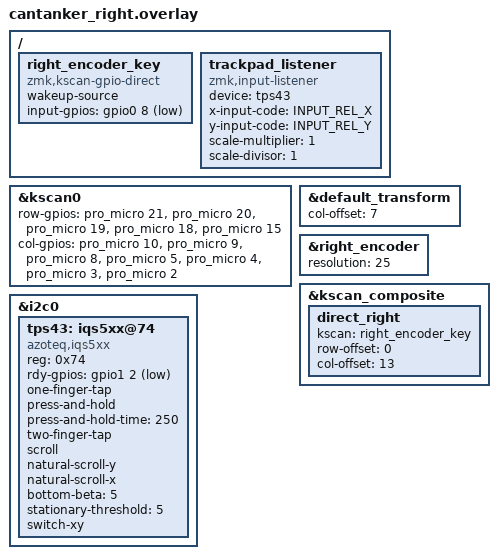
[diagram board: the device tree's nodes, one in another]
#include "cantanker.dtsi"
#include <dt-bindings/input/input-event-codes.h>

&kscan0 {
    row-gpios
        = <&pro_micro 21 (GPIO_ACTIVE_HIGH | GPIO_PULL_DOWN)>
        , <&pro_micro 20 (GPIO_ACTIVE_HIGH | GPIO_PULL_DOWN)>
        , <&pro_micro 19 (GPIO_ACTIVE_HIGH | GPIO_PULL_DOWN)>
        , <&pro_micro 18 (GPIO_ACTIVE_HIGH | GPIO_PULL_DOWN)>
        , <&pro_micro 15 (GPIO_ACTIVE_HIGH | GPIO_PULL_DOWN)>
        ;

    col-gpios
        = <&pro_micro 10 GPIO_ACTIVE_HIGH>
        , <&pro_micro 9  GPIO_ACTIVE_HIGH>
        , <&pro_micro 8  GPIO_ACTIVE_HIGH>
        , <&pro_micro 5  GPIO_ACTIVE_HIGH>
        , <&pro_micro 4  GPIO_ACTIVE_HIGH>
        , <&pro_micro 3  GPIO_ACTIVE_HIGH>
        , <&pro_micro 2  GPIO_ACTIVE_HIGH>
        ;
};

&default_transform {
    col-offset = <7>;
};

&right_encoder {
    status = "okay";
    resolution = <25>;
};

/ {
    right_encoder_key: right_encoder_key {
        compatible = "zmk,kscan-gpio-direct";
        wakeup-source;
        input-gpios = <&gpio0 8 (GPIO_ACTIVE_LOW | GPIO_PULL_UP)>;
    };
};

&kscan_composite {
    direct_right {
        kscan = <&right_encoder_key>;
        row-offset = <0>;
        col-offset = <13>;
    };
};

&i2c0 {
    status = "okay";
    
    tps43: iqs5xx@74 {
        status = "okay";
        compatible = "azoteq,iqs5xx";
        reg = <0x74>;

        rdy-gpios = <&gpio1 2 (GPIO_ACTIVE_LOW | GPIO_PULL_UP)>;

        /*
         * Potentially non-exhaustive list of configuration options.
         * See: dts/bindings/input/azoteq,iqs5xx-common.yaml for a full list.
         */
        one-finger-tap;
        press-and-hold;
        press-and-hold-time = <250>;
        two-finger-tap;

        scroll;
        natural-scroll-y;
        natural-scroll-x;

        bottom-beta = <5>;
        stationary-threshold = <5>;

        switch-xy;
    };
};

/ {
    trackpad_listener {
        compatible = "zmk,input-listener";
        device = <&tps43>;
        
        x-input-code = <INPUT_REL_X>;
        y-input-code = <INPUT_REL_Y>;
        scale-multiplier = <1>;
        scale-divisor = <1>;
    };
};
